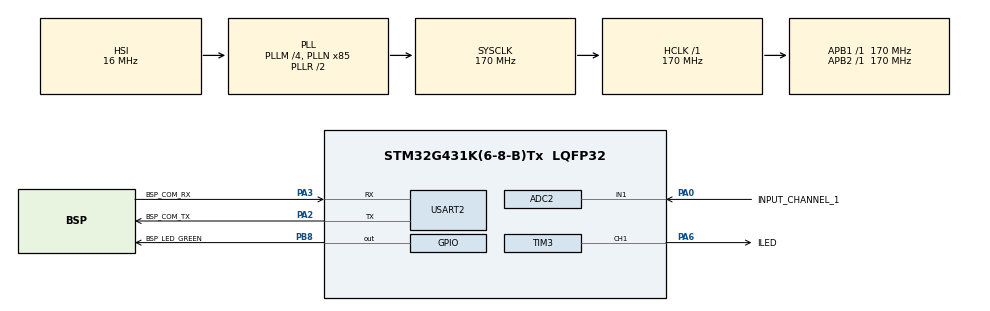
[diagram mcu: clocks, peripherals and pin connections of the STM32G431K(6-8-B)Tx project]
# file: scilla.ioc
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ADC2.Channel-0\#ChannelRegularConversion=ADC_CHANNEL_1
ADC2.DMAContinuousRequests=ENABLE
ADC2.ExternalTrigConv=ADC_EXTERNALTRIG_T3_TRGO
ADC2.NbrOfConversionFlag=1
ADC2.OffsetNumber-0\#ChannelRegularConversion=ADC_OFFSET_NONE
ADC2.Rank-0\#ChannelRegularConversion=1
ADC2.SamplingTime-0\#ChannelRegularConversion=ADC_SAMPLETIME_2CYCLES_5
Dma.ADC2.0.Direction=DMA_PERIPH_TO_MEMORY
Dma.ADC2.0.EventEnable=DISABLE
Dma.ADC2.0.Instance=DMA1_Channel1
Dma.ADC2.0.MemDataAlignment=DMA_MDATAALIGN_HALFWORD
Dma.ADC2.0.MemInc=DMA_MINC_ENABLE
Dma.ADC2.0.Mode=DMA_CIRCULAR
Dma.ADC2.0.PeriphDataAlignment=DMA_PDATAALIGN_HALFWORD
Dma.ADC2.0.PeriphInc=DMA_PINC_DISABLE
Dma.ADC2.0.Polarity=HAL_DMAMUX_REQ_GEN_RISING
Dma.ADC2.0.Priority=DMA_PRIORITY_HIGH
Dma.ADC2.0.RequestNumber=1
Dma.ADC2.0.SignalID=NONE
Dma.ADC2.0.SyncEnable=DISABLE
Dma.ADC2.0.SyncPolarity=HAL_DMAMUX_SYNC_NO_EVENT
Dma.ADC2.0.SyncRequestNumber=1
Dma.ADC2.0.SyncSignalID=NONE
Dma.Request0=ADC2
FREERTOS.HEAP_NUMBER=1
FREERTOS.Tasks01=defaultTask,24,128,StartDefaultTask,Default,NULL,Dynamic,NULL,NULL
FREERTOS.configMAX_TASK_NAME_LEN=30
FREERTOS.configTOTAL_HEAP_SIZE=2048
FREERTOS.configUSE_NEWLIB_REENTRANT=1
Mcu.Family=STM32G4
Mcu.Name=STM32G431K(6-8-B)Tx
Mcu.Package=LQFP32
NVIC.ADC1_2_IRQn=true\:5\:0\:false\:false\:true\:true\:true\:true\:true
NVIC.DMA1_Channel1_IRQn=true\:5\:0\:false\:false\:true\:true\:false\:true\:true
NVIC.PriorityGroup=NVIC_PRIORITYGROUP_4
NVIC.TIM6_DAC_IRQn=true\:15\:0\:false\:false\:true\:false\:false\:true\:true
NVIC.TimeBase=TIM6_DAC_IRQn
NVIC.TimeBaseIP=TIM6
NVIC.USART2_IRQn=true\:5\:0\:false\:false\:true\:true\:true\:true\:true
PA0.GPIO_Label=INPUT_CHANNEL_1
PA0.Mode=IN1-Single-Ended
PA0.Signal=ADC2_IN1
PA13.GPIO_Label=T_SWDIO
PA13.Mode=Serial_Wire
PA13.Signal=SYS_JTMS-SWDIO
PA14.GPIO_Label=T_SWCLK
PA14.Mode=Serial_Wire
PA14.Signal=SYS_JTCK-SWCLK
PA2.GPIO_Label=BSP_COM_TX
PA2.Mode=Asynchronous
PA2.Signal=USART2_TX
PA3.GPIO_Label=BSP_COM_RX
PA3.Mode=Asynchronous
PA3.Signal=USART2_RX
PA6.GPIO_Label=ILED
PA6.Signal=S_TIM3_CH1
PB3.GPIO_Label=T_SWO
PB3.Signal=SYS_JTDO-SWO
PB8-BOOT0.GPIO_Label=BSP_LED_GREEN
PB8-BOOT0.Signal=GPIO_Output
ProjectManager.HeapSize=0x200
ProjectManager.StackSize=0x400
ProjectManager.TargetToolchain=CMake
RCC.ADC12Freq_Value=170000000
RCC.AHBFreq_Value=170000000
RCC.APB1Freq_Value=170000000
RCC.APB1TimFreq_Value=170000000
RCC.APB2Freq_Value=170000000
RCC.APB2TimFreq_Value=170000000
RCC.CortexFreq_Value=170000000
RCC.EXTERNAL_CLOCK_VALUE=12288000
RCC.HCLKFreq_Value=170000000
RCC.HSE_VALUE=8000000
RCC.HSI48_VALUE=48000000
RCC.HSI_VALUE=16000000
RCC.LSE_VALUE=32768
RCC.LockedElements=AHBOutput,HCLKOutput,CortexSysOutput,PWRCLKoutput,FCLKCortexOutput,APB1Output,TimPrescOut1,APB2Output,TimPrescOut2,USART2output
RCC.PLLM=RCC_PLLM_DIV4
RCC.PLLN=85
RCC.SYSCLKFreq_VALUE=170000000
RCC.SYSCLKSource=RCC_SYSCLKSOURCE_PLLCLK
RCC.USBFreq_Value=170000000
RCC.VCOOutputFreq_Value=340000000
SH.S_TIM3_CH1.0=TIM3_CH1,PWM Generation1 CH1
TIM3.Channel-Output\ Compare2\ No\ Output=TIM_CHANNEL_2
TIM3.Channel-PWM\ Generation1\ CH1=TIM_CHANNEL_1
TIM3.OCMode_2=TIM_OCMODE_TIMING
TIM3.OCPolarity_1=TIM_OCPOLARITY_LOW
TIM3.PeriodNoDither=1000
TIM3.Prescaler=1700
TIM3.PulseNoDither_1=32
TIM3.PulseNoDither_2=28
TIM3.TIM_MasterOutputTrigger=TIM_TRGO_OC2REF
USART2.FIFOMode=FIFOMODE_DISABLE
USART2.VirtualMode-Asynchronous=VM_ASYNC
VP_FREERTOS_VS_CMSIS_V2.Mode=CMSIS_V2
VP_SYS_VS_DBSignals.Mode=DisableDeadBatterySignals
VP_SYS_VS_tim6.Mode=TIM6
VP_TIM3_VS_ClockSourceINT.Mode=Internal
VP_TIM3_VS_no_output2.Mode=Output Compare2 No Output
board=NUCLEO-G431KB

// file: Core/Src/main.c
/* USER CODE BEGIN Header */
/**
  ******************************************************************************
  * @file           : main.c
  * @brief          : Main program body
  ******************************************************************************
  * @attention
  *
  * Copyright (c) 2025 STMicroelectronics.
  * All rights reserved.
  *
  * This software is licensed under terms that can be found in the LICENSE file
  * in the root directory of this software component.
  * If no LICENSE file comes with this software, it is provided AS-IS.
  *
  ******************************************************************************
  */
/* USER CODE END Header */
#include "main.h"
#include "cmsis_os.h"
#include "adc.h"
#include "dma.h"
#include "tim.h"
#include "usart.h"
#include "gpio.h"

/* USER CODE BEGIN Includes */
#include "stdio.h"
#include "stm32g4xx_nucleo.h"

#include "InitCppWrapper.h"
/* USER CODE END Includes */

void SystemClock_Config(void);
void MX_FREERTOS_Init(void);

int main(void)
{

  /* MCU Configuration--------------------------------------------------------*/

  /* Reset of all peripherals, Initializes the Flash interface and the Systick. */
  HAL_Init();

  /* Configure the system clock */
  SystemClock_Config();

  /* Initialize all configured peripherals */
  MX_GPIO_Init();
  MX_DMA_Init();
  MX_USART2_UART_Init();
  MX_ADC2_Init();
  MX_TIM3_Init();
  /* USER CODE BEGIN 2 */
  BSP_LED_Init(LED_GREEN);
  BSP_LED_Off(LED_GREEN);

  Scilla_Initialize(NULL);
  /* USER CODE END 2 */

  /* Init scheduler */
  osKernelInitialize();

  /* Call init function for freertos objects (in cmsis_os2.c) */
  MX_FREERTOS_Init();

  /* Start scheduler */
  osKernelStart();

  /* We should never get here as control is now taken by the scheduler */

  /* Infinite loop */
  while (1)
  {

  }
}

void SystemClock_Config(void)
{
  RCC_OscInitTypeDef RCC_OscInitStruct = {0};
  RCC_ClkInitTypeDef RCC_ClkInitStruct = {0};

  /** Configure the main internal regulator output voltage
  */
  HAL_PWREx_ControlVoltageScaling(PWR_REGULATOR_VOLTAGE_SCALE1_BOOST);

  /** Initializes the RCC Oscillators according to the specified parameters
  * in the RCC_OscInitTypeDef structure.
  */
  RCC_OscInitStruct.OscillatorType = RCC_OSCILLATORTYPE_HSI;
  RCC_OscInitStruct.HSIState = RCC_HSI_ON;
  RCC_OscInitStruct.HSICalibrationValue = RCC_HSICALIBRATION_DEFAULT;
  RCC_OscInitStruct.PLL.PLLState = RCC_PLL_ON;
  RCC_OscInitStruct.PLL.PLLSource = RCC_PLLSOURCE_HSI;
  RCC_OscInitStruct.PLL.PLLM = RCC_PLLM_DIV4;
  RCC_OscInitStruct.PLL.PLLN = 85;
  RCC_OscInitStruct.PLL.PLLP = RCC_PLLP_DIV2;
  RCC_OscInitStruct.PLL.PLLQ = RCC_PLLQ_DIV2;
  RCC_OscInitStruct.PLL.PLLR = RCC_PLLR_DIV2;
  if (HAL_RCC_OscConfig(&RCC_OscInitStruct) != HAL_OK)
  {
    Error_Handler();
  }

  /** Initializes the CPU, AHB and APB buses clocks
  */
  RCC_ClkInitStruct.ClockType = RCC_CLOCKTYPE_HCLK|RCC_CLOCKTYPE_SYSCLK
                              |RCC_CLOCKTYPE_PCLK1|RCC_CLOCKTYPE_PCLK2;
  RCC_ClkInitStruct.SYSCLKSource = RCC_SYSCLKSOURCE_PLLCLK;
  RCC_ClkInitStruct.AHBCLKDivider = RCC_SYSCLK_DIV1;
  RCC_ClkInitStruct.APB1CLKDivider = RCC_HCLK_DIV1;
  RCC_ClkInitStruct.APB2CLKDivider = RCC_HCLK_DIV1;

  if (HAL_RCC_ClockConfig(&RCC_ClkInitStruct, FLASH_LATENCY_4) != HAL_OK)
  {
    Error_Handler();
  }
}

void HAL_TIM_PeriodElapsedCallback(TIM_HandleTypeDef *htim)
{
  if (htim->Instance == TIM6)
  {
    HAL_IncTick();
  }
}

void Error_Handler(void)
{
  __disable_irq();
  while (1)
  {
  }
}
